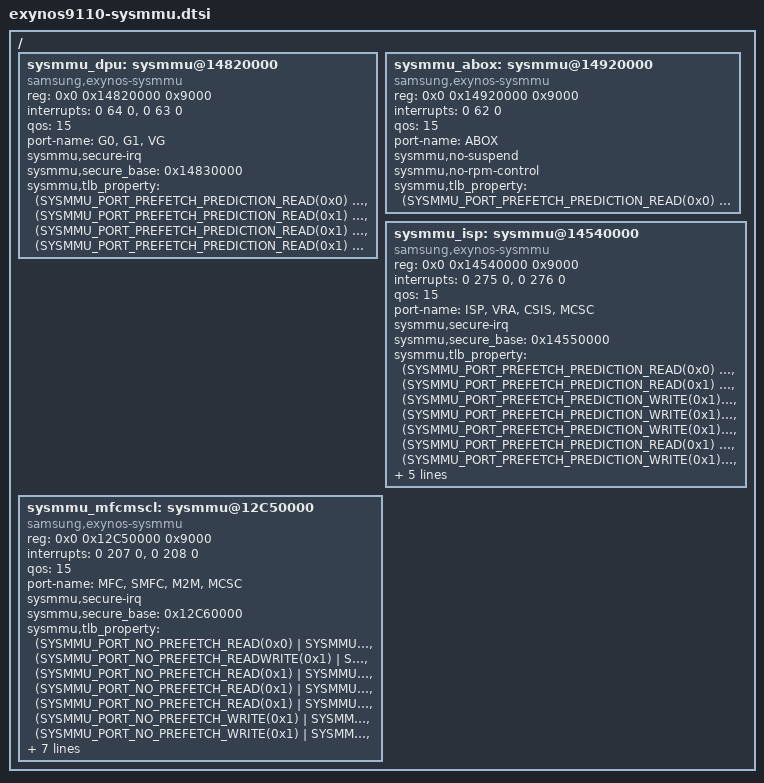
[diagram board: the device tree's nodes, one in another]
/*
 * SAMSUNG EXYNOS9110 SoC device tree source
 *
 * Copyright (c) 2018 Samsung Electronics Co., Ltd.
 *		http://www.samsung.com
 *
 * SAMSUNG EXYNOS9110 SoC device nodes are listed in this file.
 * EXYNOS9110 based board files can include this file and provide
 * values for board specfic bindings.
 *
 * This program is free software; you can redistribute it and/or modify
 * it under the terms of the GNU General Public License version 2 as
 * published by the Free Software Foundation.
 */

#include <dt-bindings/clock/exynos9110.h>
#include <dt-bindings/interrupt-controller/arm-gic.h>
#include <dt-bindings/sysmmu/sysmmu.h>

/ {
	sysmmu_dpu: sysmmu@14820000 {
		compatible = "samsung,exynos-sysmmu";
		reg = <0x0 0x14820000 0x9000>;
		interrupts = <0 64 0>,
			     <0 63 0>;
		qos = <15>;
/*
		clock-names = "aclk";
		clocks = <&clock GATE_SMMU_D_XXXXX_QCH>;
*/
		port-name = "G0, G1, VG";
		sysmmu,secure-irq;
		sysmmu,secure_base = <0x14830000>;
		sysmmu,tlb_property =
			<(SYSMMU_PORT_PREFETCH_PREDICTION_READ(0x0) | SYSMMU_BL1) SYSMMU_NOID>,
			<(SYSMMU_PORT_PREFETCH_PREDICTION_READ(0x1) | SYSMMU_BL1) SYSMMU_ID(0x2)>,
			<(SYSMMU_PORT_PREFETCH_PREDICTION_READ(0x1) | SYSMMU_BL1) SYSMMU_ID(0x6)>,
			<(SYSMMU_PORT_PREFETCH_PREDICTION_READ(0x1) | SYSMMU_BL1) SYSMMU_ID(0x8)>;
		#iommu-cells = <0>;
	};

	sysmmu_abox: sysmmu@14920000 {
		compatible = "samsung,exynos-sysmmu";
		reg = <0x0 0x14920000 0x9000>;
		interrupts = <0 62 0>;
		qos = <15>;
/*
		clock-names = "aclk";
		clocks = <&clock GATE_SMMU_D_XXXXX_QCH>;
*/
		port-name = "ABOX";
		sysmmu,no-suspend;
		sysmmu,no-rpm-control;
		sysmmu,tlb_property =
			<(SYSMMU_PORT_PREFETCH_PREDICTION_READ(0x0) | SYSMMU_BL1) SYSMMU_NOID>;
		#iommu-cells = <0>;
	};

	sysmmu_isp: sysmmu@14540000 {
		compatible = "samsung,exynos-sysmmu";
		reg = <0x0 0x14540000 0x9000>;
		interrupts = <0 275 0>,
			     <0 276 0>;
		qos = <15>;
/*
		clock-names = "aclk";
		clocks = <&clock GATE_SMMU_D_XXXXX_QCH>;
*/
		port-name = "ISP, VRA, CSIS, MCSC";
		sysmmu,secure-irq;
		sysmmu,secure_base = <0x14550000>;
		sysmmu,tlb_property =
			<(SYSMMU_PORT_PREFETCH_PREDICTION_READ(0x0)  | SYSMMU_BL1) SYSMMU_NOID>,
			<(SYSMMU_PORT_PREFETCH_PREDICTION_READ(0x1)  | SYSMMU_BL1) SYSMMU_ID_MASK(0x5, 0xF)>,
			<(SYSMMU_PORT_PREFETCH_PREDICTION_WRITE(0x1) | SYSMMU_BL1) SYSMMU_ID_MASK(0x1, 0xF)>,
			<(SYSMMU_PORT_PREFETCH_PREDICTION_WRITE(0x1) | SYSMMU_BL1) SYSMMU_ID_MASK(0x5, 0xF)>,
			<(SYSMMU_PORT_PREFETCH_PREDICTION_WRITE(0x1) | SYSMMU_BL1) SYSMMU_ID_MASK(0x9, 0xF)>,
			<(SYSMMU_PORT_PREFETCH_PREDICTION_READ(0x1)  | SYSMMU_BL1) SYSMMU_ID_MASK(0x3, 0x3)>,
			<(SYSMMU_PORT_PREFETCH_PREDICTION_WRITE(0x1) | SYSMMU_BL1) SYSMMU_ID_MASK(0x3, 0x3)>,
			<(SYSMMU_PORT_PREFETCH_PREDICTION_WRITE(0x1) | SYSMMU_BL1) SYSMMU_ID_MASK(0x0, 0xF)>,
			<(SYSMMU_PORT_PREFETCH_PREDICTION_WRITE(0x1) | SYSMMU_BL1) SYSMMU_ID_MASK(0x4, 0xF)>,
			<(SYSMMU_PORT_PREFETCH_PREDICTION_WRITE(0x1) | SYSMMU_BL1) SYSMMU_ID_MASK(0x2, 0xF)>,
			<(SYSMMU_PORT_PREFETCH_PREDICTION_WRITE(0x1) | SYSMMU_BL1) SYSMMU_ID_MASK(0x6, 0xF)>,
			<(SYSMMU_PORT_PREFETCH_PREDICTION_WRITE(0x1) | SYSMMU_BL1) SYSMMU_ID_MASK(0xA, 0xF)>;
		#iommu-cells = <0>;
	};

	sysmmu_mfcmscl: sysmmu@12C50000 {
		compatible = "samsung,exynos-sysmmu";
		reg = <0x0 0x12C50000 0x9000>;
		interrupts = <0 207 0>,
			     <0 208 0>;
		qos = <15>;
/*
		clock-names = "aclk";
		clocks = <&clock GATE_SMMU_D_XXXXX_QCH>;
*/
		port-name = "MFC, SMFC, M2M, MCSC";
		sysmmu,secure-irq;
		sysmmu,secure_base = <0x12C60000>;
		sysmmu,tlb_property =
			/* MFC */
			<(SYSMMU_PORT_NO_PREFETCH_READ(0x0) | SYSMMU_BL8) SYSMMU_NOID>,
			/* SMFC */
			<(SYSMMU_PORT_NO_PREFETCH_READWRITE(0x1) | SYSMMU_BL2) SYSMMU_ID_MASK(0x1,  0x2)>,
			/* M2M scaler */
			<(SYSMMU_PORT_NO_PREFETCH_READ(0x1)  | SYSMMU_BL4) SYSMMU_ID_MASK(0x3,  0x3F)>,
			<(SYSMMU_PORT_NO_PREFETCH_READ(0x1)  | SYSMMU_BL1) SYSMMU_ID_MASK(0x7,  0x3F)>,
			<(SYSMMU_PORT_NO_PREFETCH_READ(0x1)  | SYSMMU_BL1) SYSMMU_ID_MASK(0xB,  0x3F)>,
			<(SYSMMU_PORT_NO_PREFETCH_WRITE(0x1) | SYSMMU_BL4) SYSMMU_ID_MASK(0x23, 0x3F)>,
			<(SYSMMU_PORT_NO_PREFETCH_WRITE(0x1) | SYSMMU_BL1) SYSMMU_ID_MASK(0x27, 0x3F)>,
			<(SYSMMU_PORT_NO_PREFETCH_WRITE(0x1) | SYSMMU_BL1) SYSMMU_ID_MASK(0x2B, 0x3F)>,
			/* MCSC */
			<(SYSMMU_PORT_PREFETCH_PREDICTION_READ(0x1)  | SYSMMU_BL1) SYSMMU_ID_MASK(0x2, 0xF)>,
			<(SYSMMU_PORT_PREFETCH_PREDICTION_READ(0x1)  | SYSMMU_BL1) SYSMMU_ID_MASK(0x6, 0xF)>,
			<(SYSMMU_PORT_PREFETCH_PREDICTION_READ(0x1)  | SYSMMU_BL1) SYSMMU_ID_MASK(0xA, 0xF)>,
			<(SYSMMU_PORT_PREFETCH_PREDICTION_WRITE(0x1) | SYSMMU_BL1) SYSMMU_ID_MASK(0x2, 0xF)>,
			<(SYSMMU_PORT_PREFETCH_PREDICTION_WRITE(0x1) | SYSMMU_BL1) SYSMMU_ID_MASK(0x6, 0xF)>,
			<(SYSMMU_PORT_PREFETCH_PREDICTION_WRITE(0x1) | SYSMMU_BL1) SYSMMU_ID_MASK(0xA, 0xF)>;
		#iommu-cells = <0>;
	};
};
